# RL6955_IP_SVD register map
Vendor: Realtek
Registers are 32-bit, read-write, reset 0x0 unless marked. A register's access mark holds for its fields unless they carry their own. Offsets are from the block's base; [hi:lo] are bit positions; {n}, {i} and the like mark numbered series.

## LCDC_REG
Base 0x41888000
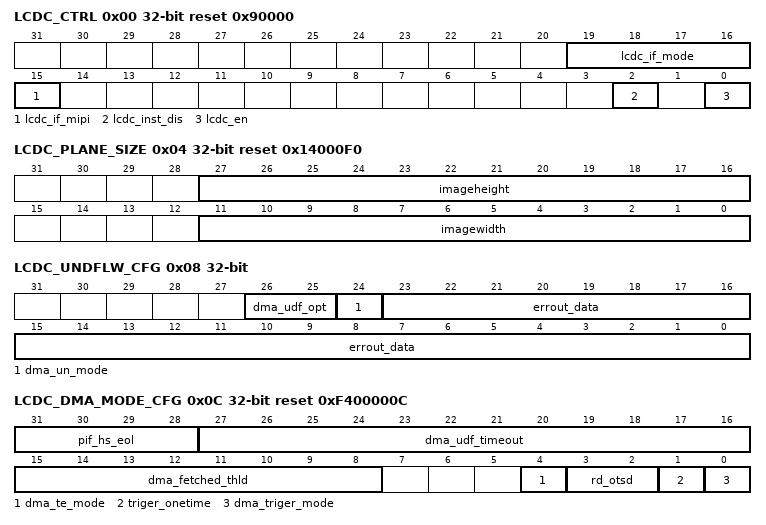
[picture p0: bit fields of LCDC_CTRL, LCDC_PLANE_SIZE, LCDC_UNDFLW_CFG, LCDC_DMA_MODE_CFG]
0x00 LCDC_CTRL reset 0x90000 — LCDC control register
  [19:16] lcdc_if_mode — *0000: 8-bit MCU (RGB565/RGB888 support) *0001: 16-bit MCU (RGB565 support) *0010: 9-bit MCU (RGB666 support) *0011: 18-bit MCU (RGB666 support) *0100: 24-bit MCU (RGB888 support) *1000: 6-bit RGB parallel interface (RGB565/RGB666 support) *1001: 16-bit RGB parallel interface (RGB565 support) *1010: 18-bit RGB parallel interface (RGB666 support) *1011: 8-bit RGB parallel interface (RGB888 support) *1100: 24-bit RGB parallel interface (RGB888 support) *Others: Reserved
  [15] lcdc_if_mipi
  [2] lcdc_inst_dis — Disable LCDC instantly. Reset LCDC internal states and disable LCDC then clear both this bit and LCDCEN.
  [0] lcdc_en — Write 1 to enable LCDC.
0x04 LCDC_PLANE_SIZE reset 0x14000F0
  [27:16] imageheight — The height of panel (Y-channel based), the min. value is 0x1.
  [11:0] imagewidth — The width of panel (X-channel based), the min. value is 0x1. *For LCD, it means pixel number per line.
0x08 LCDC_UNDFLW_CFG — LCDC underflow configuration register
  [26:25] dma_udf_opt — 0: output error data at current frame when dma underflow occurs 1: pause panel interface(clk and data) until underflow timeout counter reaches threshold value, then entering error mode 2: entering drop mode immediately when dma underflow occurs 3: pause panel interface(clk and data) until underflow timeout counter reaches threshold value, then entering drop mode
  [24] dma_un_mode — *0:Output last data *1:Output erroutdata
  [23:0] errout_data — Output data when DMA FIFO underflow occurred. (directly mapping to output D[23:0])
0x0C LCDC_DMA_MODE_CFG reset 0xF400000C — LCDC DMA mode configuration register
  [31:28] pif_hs_eol — threshold value to check if panelif hs_cnt almost reaching end of line
  [27:16] dma_udf_timeout — threshold value for dma underflow timeout counter
  [15:8] dma_fetched_thld — threshold value for dma data_fetched indicator(start panelif FSM)
  [4] dma_te_mode — 1: TE trigger-mode open, DMA refreshes frame manually based on panel TE input 0: use dma_triger_mode(bit 0 setting, auto or onetime)
  [3:2] rd_otsd — The value of read outstanding -1, for DMA burst size configuration
  [1] triger_onetime — Write '1', hardware DMA one frame from DMA buffer based on synchronous signal. After DMA completed,this bit is cleared automatically.
  [0] dma_triger_mode — DMA Trigger-mode enable. *0: Auto-mode, open, DMA refreshes automatically based on synchronous signal. *1: Trigger-mode open, DMA refreshes frame manually based on TRIGER_ONETIME bit of this register. Trigger mode is useful for LCD with internal GRAM.
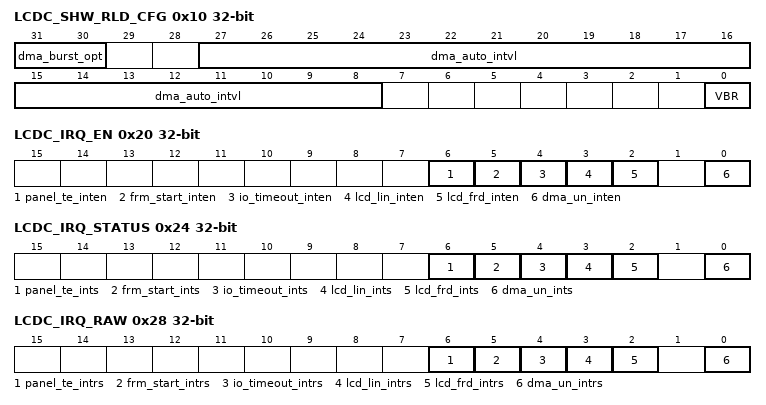
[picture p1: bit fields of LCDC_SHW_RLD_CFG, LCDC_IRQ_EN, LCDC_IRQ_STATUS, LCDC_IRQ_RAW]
0x10 LCDC_SHW_RLD_CFG — LCDC shadow reload configuration register
  [31:30] dma_burst_opt — 0: axi 64-byte burst 1: axi 128-byte burst 2: axi 256-byte burst
  [27:8] dma_auto_intvl — interval between two dma transfer in auto-mode
  [0] VBR — vertical blanking reload. This bit is set by software and cleared only by hardware after reload (it cannot be cleared through register write once it is set). 0: no effect 1: The shadow registers are reloaded during the vertical blanking period (at the beginning of the first line after the active display area).
0x14 LCDC_COLOR_CFG — color config
  [5:2] color_format — 0000: RGB888 0001: RGB565 0010: RGB666 1000: BGR888 1001: BGR565 1010: BGR666
0x20 LCDC_IRQ_EN — LCDC interrupt enable register
  [6] panel_te_inten — panel TE input interrupt Enable
  [5] frm_start_inten — DMA Frame start interrupt Enable. This bit can be set and cleared by software. * 0: DMA Frame start interrupt disable * 1: DMA Frame start interrupt enable
  [4] io_timeout_inten — Write or read timeout interrupt Enable in MCU I/F I/O mode. This bit can be set and cleared by software. * 0: MCU I/O mode write/read timeout interrupt disable * 1: MCU I/O mode write/read timeout interrupt enable
  [3] lcd_lin_inten — Line Interrupt Enable. This bit can be set and cleared by software. * 0: Line interrupt disable * 1: Line Interrupt enable
  [2] lcd_frd_inten — LCD refresh frame done interrupt enable
  [0] dma_un_inten — DMA FIFO underflow interrupt enable
0x24 LCDC_IRQ_STATUS ro — LCDC interrupt status register
  [6] panel_te_ints — panel TE input interrupt status. Write 1 to clear it. * 0: No panel TE input interrupt generated * 1: A panel TE input interrupt is generated
  [5] frm_start_ints — DMA frame start interrupt status. Write 1 to clear it. * 0: No DMA frame start interrupt generated * 1: A DMA frame start interrupt is generated
  [4] io_timeout_ints — Write or read timeout interrupt status in MCU I/F I/O mode. Write 1 to clear it. * 0: No write/read timeout interrupt generated. * 1: A write/read timeout interrupt is generated.
  [3] lcd_lin_ints — Line Interrupt status. Write 1 to clear it. * 0: No Line interrupt generated * 1: A Line interrupt is generated, when a programmed line is reached Note: When this bit is set and DMA fetches the first pixel data of the specified line number from frame buffer, the line interrupt happens. The line number depends on LCDC_LINE_INT_POS register value.
  [2] lcd_frd_ints — LCD refresh frame done interrupt status. Write 1 to clear it. * 0: No LCD refresh frame done interrupt generated. * 1: This interrupt generated, when sending LCD frame done. Note: When this bit is set and DMA fetch the last pixel data from frame buffer, the After LCD refresh frame done, interrupt happens.
  [0] dma_un_ints — DMA FIFO underflow interrupt status. Write 1 to clear it. * 0: No DMA FIFO underflow interrupt generated * 1: Interrupt generated when DMA FIFO underflow happens
0x28 LCDC_IRQ_RAW ro — LCDC raw interrupt register
  [6] panel_te_intrs — panel TE input raw interrupt status. No matter panel TE input interrupt is enabled or disabled, this bit is set when panel TE input interrupt happens. Writting 1 to the PANEL_TE_INTS field in register LCDC_IRQ_STATUS is to clear this bit.
  [5] frm_start_intrs — DMA frame start raw interrupt status. No matter DMA frame start interrupt is enabled or disabled, this bit is set when DMA frame start interrupt happens. Writting 1 to the FRM_START_INTS field in register LCDC_IRQ_STATUS is to clear this bit.
  [4] io_timeout_intrs — Write or read timeout interrupt raw interrupt status in MCU I/F I/O mode. No matter the I/O write/read timeout interrupt is enabled or disabled, this bit is set when I/O write/read timeout interrupt happens. Write 1 to the IO_TIMEOUT_INTS field in register LCDC_IRQ_STATUS to clear this bit.
  [3] lcd_lin_intrs — Line Interrupt raw status. No matter the line interrupt is enabled or disabled, this bit is set when line interrupt happens. Writting 1 to the LCD_LIN_INTS field in register LCDC_IRQ_STATUS is to clear this bit.
  [2] lcd_frd_intrs — LCD refresh frame done raw interrupt status. No matter the refresh done interrupt is enabled or disabled, this bit is set when refresh done interrupt happens. Writting 1 to the LCD_FRD_INTS field in register LCDC_IRQ_STATUS is to clear this bit.
  [0] dma_un_intrs — DMA FIFO underflow raw interrupt status. When LCDC DMA FIFO under flow event happens, this bit is set. Write 1 to the DMAUNINTS field in register LCDC_IRQ_STATUS to clear this bit.
0x2C LCDC_LINE_INT_POS — LCDC line interrupt position register
  [11:0] line_int_pos — Line Interrupt Position These bits configure the line interrupt position.
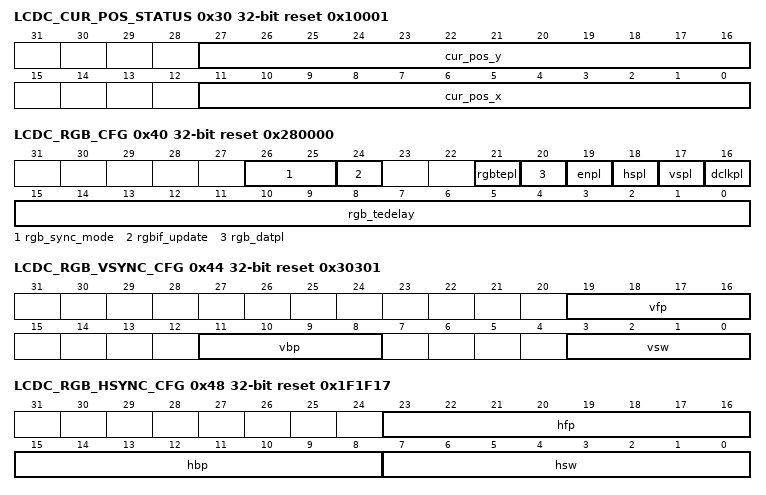
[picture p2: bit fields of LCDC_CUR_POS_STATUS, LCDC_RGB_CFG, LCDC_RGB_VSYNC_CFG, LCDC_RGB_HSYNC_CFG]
0x30 LCDC_CUR_POS_STATUS ro reset 0x10001 — Display current position
  [27:16] cur_pos_y — Current Y Position These bits return the current Y position.
  [11:0] cur_pos_x — Current X Position These bits return the current X position.
0x3C LCDC_DEBUG_STATUS ro — Debug signal
  [31:0] lcdc_debug_states — LCDC critial signal for debug
0x40 LCDC_RGB_CFG reset 0x280000 — LCDC RGB mode config
  [26:25] rgb_sync_mode — * 00: DE mode, frame synchronized with ENABLE signal * 01: HV mode, frame synchronized with synchronous signal * 10: TE mode * Others: Reserved
  [24] rgbif_update — Force Hardware updates RGB I/F parameters after current LCD refresh frame done. CPU writes 1 to force Hardware updating parameters. After updating, this bit is cleared. When the LCDC is running, if the following values related with RGB I/F mode are modified dynamically, only writing 1 to this bit can the newer value be used by hardware after the current frame refresh done. * The CLKDIV field in the LCDC_CLK_DIV register * The VFP, VBP, VSW fields in the LCDC_RGB_VSYNC_CFG register * The HBP, HFP, HSW fields in the LCDC_RGB_HSYNC_CFG register
  [21] rgbtepl — The TE pulse polarity. * 0: Low level for active pulse * 1: High level for active pulse
  [20] rgb_datpl — The Data pulse polarity. * 0: Normal * 1: Inverted
  [19] enpl — The ENABLE pulse polarity. * 0: Low level for active data * 1: High level for active data
  [18] hspl — The HSYNC pulse polarity. * 0: Low level synchronous clock * 1: High level synchronous clock
  [17] vspl — The VSYNC pulse polarity. * 0: Low level synchronous clock * 1: High level synchronous clock
  [16] dclkpl — The polarity of the DCLK active edge. * 0: Data fetched at DCLK rising edge * 1: Data fetched at DCLK falling edge
  [15:0] rgb_tedelay — The delay interval -5. This interval is from detected TE signal to starting frame transfer. Unit: WR pulse width. The maximum value is 65535. The real delay interval is TEDELAY + 4 or TEDELAY + 5.
0x44 LCDC_RGB_VSYNC_CFG reset 0x30301 — RGB Vsync config
  [19:16] vfp — Front porch line number-1. The number of inactive lines at the end of a frame, before vertical synchronization period.
  [11:8] vbp — Back porch line number-1. The number of inactive lines at the start of a frame, after vertical synchronization period.
  [3:0] vsw — Vertical synchronization signal width -1. Unit: inactive lines
0x48 LCDC_RGB_HSYNC_CFG reset 0x1F1F17 — RGB Hsync config
  [23:16] hfp — Horizontal front porch -1. The number of DCLK periods between the end of active data and the rising edge of HSYNC. HFP's minimum value is 1
  [15:8] hbp — Horizontal back porch -1. The number of DCLK periods between the falling edge of HSYNC and the start of active data. HBP's minimum value is 1
  [7:0] hsw — Horizontal synchronization signal width -1. Unit: DCLK HSW's minimum value is 1
0x4C LCDC_RGB_CLK_DIV reset 0x2 — RGB clock divide
  [11:0] clkdiv — DCLK clock divider depends on this value. The relationship between them is as follows: *0 : The DCLK clock divider is 2 *1 : The DCLK clock divider is 4 *2 : The DCLK clock divider is 6 *3 : The DCLK clock divider is 8 *... The frequency of DCLK is derived from the following equation: DCLK = SYS_CLK/((CLKDIV+1)*2) where CLKDIV is any even value between 0 and 65534.
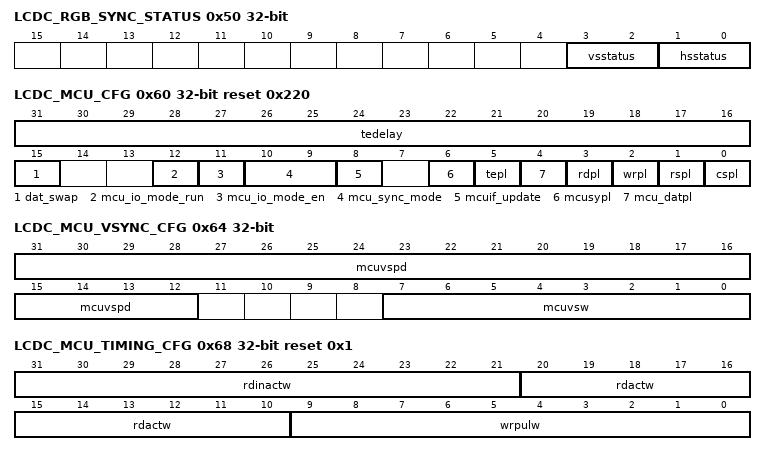
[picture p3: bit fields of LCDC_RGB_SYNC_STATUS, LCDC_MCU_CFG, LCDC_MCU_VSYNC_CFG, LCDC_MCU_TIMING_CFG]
0x50 LCDC_RGB_SYNC_STATUS ro — RGB HSYNC/VSYNC status
  [3:2] vsstatus — VSYNC Status. 00: VSYNC 01: VBP 11: ACTIVE 10: VFP
  [1:0] hsstatus — HSYNC Status. 00: HSYNC 01: HBP 11: ACTIVE 10: HFP
0x60 LCDC_MCU_CFG access per field reset 0x220 — LCDC mcu mode config
  [31:16] tedelay rw — The delay interval -5. This interval is from detected TE signal to starting frame transfer. Unit: WR pulse width. The maximum value is 65535. The real delay interval is TEDELAY + 4 or TEDELAY + 5.
  [15] dat_swap rw — swap dat[15:8] with dat[7:0] in mcu 8-bit RGB565
  [12] mcu_io_mode_run ro — MCU I/F I/O mode run * 0: DMA mode run * 1: I/O mode run
  [11] mcu_io_mode_en rw — MCU I/F I/O mode enable * 0: Disable I/O mode and open DMA mode after I/O mode FIFO empty. * 1: Enable I/O mode after current frame refresh. Poll MCU_IO_MODE_RUN after updating this bit.
  [10:9] mcu_sync_mode rw — * 00: Synchronized with the internal clock * 01: Synchronized with VSYNC input * 10: Tearing effect line on (Mode1, VSYNC) * Others: Reserved
  [8] mcuif_update rw — Force Hardware to update MCU I/F Timing shadow register at specific timing. CPU writes 1 to force Hardware updating. After Hardware updating finished, this bit is cleared. Software can't write related shadow registers when MCUIFUPDATE is still active. When the LCDC is running, if the following values related with MCU I/F mode are modified dynamically, only writing 1 to this bit can the newer value be used by hardware after the current frame refresh done. * The TEDELAY field in the LCDC_MCU_CFG register * The MCUVSW, MCUVSPD fields in the LCDC_MCU_VSYNC_CFG register * The WRPULW, RDACTW, RDINACTW fields in the LCDC_MCU_TIMING_CFG register
  [6] mcusypl rw — The MCU VSYNC pulse polarity * 0: Low level for active pulse * 1: High level for active pulse
  [5] tepl rw — The TE pulse polarity. * 0: Low level for active pulse * 1: High level for active pulse
  [4] mcu_datpl rw — The Data pulse polarity. * 0: Normal * 1: Inverted
  [3] rdpl rw — The RD pulse polarity. * 0: Data fetched at rising edge * 1: Data fetched at falling edge
  [2] wrpl rw — The WR pulse polarity. * 0: Data fetched at rising edge * 1: Data fetched at falling edge
  [1] rspl rw — The RS pulse polarity. * 0: Low level for command address * 1: High level for command parameter
  [0] cspl rw — The CS pulse polarity. * 0: Low level for active pulse * 1: High level for active pulse
0x64 LCDC_MCU_VSYNC_CFG — MCU Vsync config
  [31:12] mcuvspd — * MCUIFMODE = 1: VSYNC idle period. This value equals to VSYNC period - IMAGEWIDTH * IMAGEHEIGHT * WR_pulse_per_pixel-5. Unit: WR pulse width. * MCUIFMODE = 0: The buffer time between frames. This value equals to the time of a frame's end to the next start -5. Unit: WR pulse width. * MCUIFMODE = 2: Invalid usage. The maximum value is 1048571.
  [7:0] mcuvsw — VSYNC signal width - 1. Unit: WR pulse width. (only for MCU VSYNC mode)
0x68 LCDC_MCU_TIMING_CFG reset 0x1 — MCU timing config
  [31:21] rdinactw — RD inactive pulse width -1. Unit: system clock
  [20:10] rdactw — RD active pulse width -1. Unit: system clock
  [9:0] wrpulw — Write clock divider depends on this value. The relationship between them is as follows: * 0: The write clock divider is 2 * 1: The write clock divider is 4 * 2: The write clock divider is 6 * 3: The write clock divider is 8 *... The frequency of write clock is derived from the following equation: Write clock = SYS_CLK/((WRPULW+1) * 2) where WRPULW is any even value between 0 and 1022.
0x6C LCDC_MCU_IO_DATA ro — MCU IO mode config
  [23:0] mcu_rw_data — When reading this register, this lower 24 bits represent the data read from LCM through MCU I/O mode I/F. Note: When TX FIFO not full and I/O timeout interrupt not happen ,this data can be read.
0x70 LCDC_MCU_IO_TO_CFG reset 0x42 — MCU IO timeout config
  [15:0] io_timeout_num — The I/O write/read timeout interrupthappens, When writing or reading is timeout for IO_RDY_TO_DOTCLK_NUM system clocks in MCU I/F I/O mode, t. When MCU I/F I/O mode is used, the recommand value is: 16 * WRPULW + RDACTW + RDINACTW
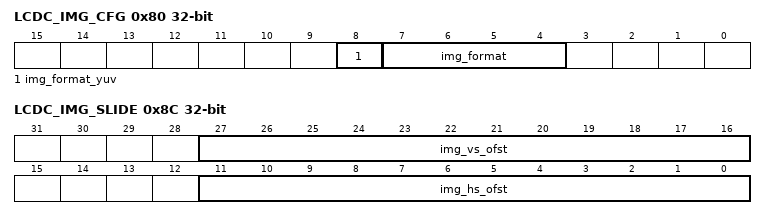
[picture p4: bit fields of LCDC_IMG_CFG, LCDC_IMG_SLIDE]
0x80 LCDC_IMG_CFG — source image config
  [8] img_format_yuv — enable yuv422torgb888
  [7:4] img_format — Image layer data format, it supports the following values: *0000: ARGB8888 *0001: RGB888 *0010: RGB565 *0011: ARGB1555 *0100: ARGB4444 *0101: RGB666 *0110: ARGB8666 *1000: ABGR8888 *1001: BGR888 *1010: BGR565 *Others: Reserved
0x84 LCDC_IMG_A_BASE_ADDR — LCDC image A base address
  [31:0] img_a_base_addr — Image layer DMA source address. After a frame refresh done, hardware loads the newer base address from this register automatically.
0x88 LCDC_IMG_B_BASE_ADDR — LCDC image B base address
  [31:0] img_b_base_addr — Image layer DMA source address. After a frame refresh done, hardware loads the newer base address from this register automatically.
0x8C LCDC_IMG_SLIDE — LCDC image slide
  [27:16] img_vs_ofst — pixel offset for image vertical slide
  [11:0] img_hs_ofst — pixel offset for image horizontal slide
0xE0 LCDC_MCU_CMD_DWORD0_0 8-bit — mcu predefined cmd
  [7:0] mcu_cmd_dword0_0 — mcu predefined cmd before data
{0xE1+4i} LCDC_MCU_CMD_DWORD{i}_1 8-bit (i=0..3)
  [7:0] mcu_cmd_dword{i}_1 — mcu predefined cmd before data
{0xE2+4i} LCDC_MCU_CMD_DWORD{i}_2 8-bit (i=0..3)
  [7:0] mcu_cmd_dword{i}_2 — mcu predefined cmd before data
{0xE3+4i} LCDC_MCU_CMD_DWORD{i}_3 8-bit (i=0..3)
  [7:0] mcu_cmd_dword{i}_3 — mcu predefined cmd before data
{0xE0+4i} LCDC_MCU_CMD_DWORD{i}_0 8-bit (i=1..3)
  [7:0] mcu_cmd_dword{i}_0 — mcu predefined cmd before data
0xF0 LCDC_MCU_CMD_WRNUM — number of mcu predefined cmd
  [7:0] mcu_cmd_wrnum — number of mcu predefined cmd, unit: byte
0xFC LCDC_DUMMY
